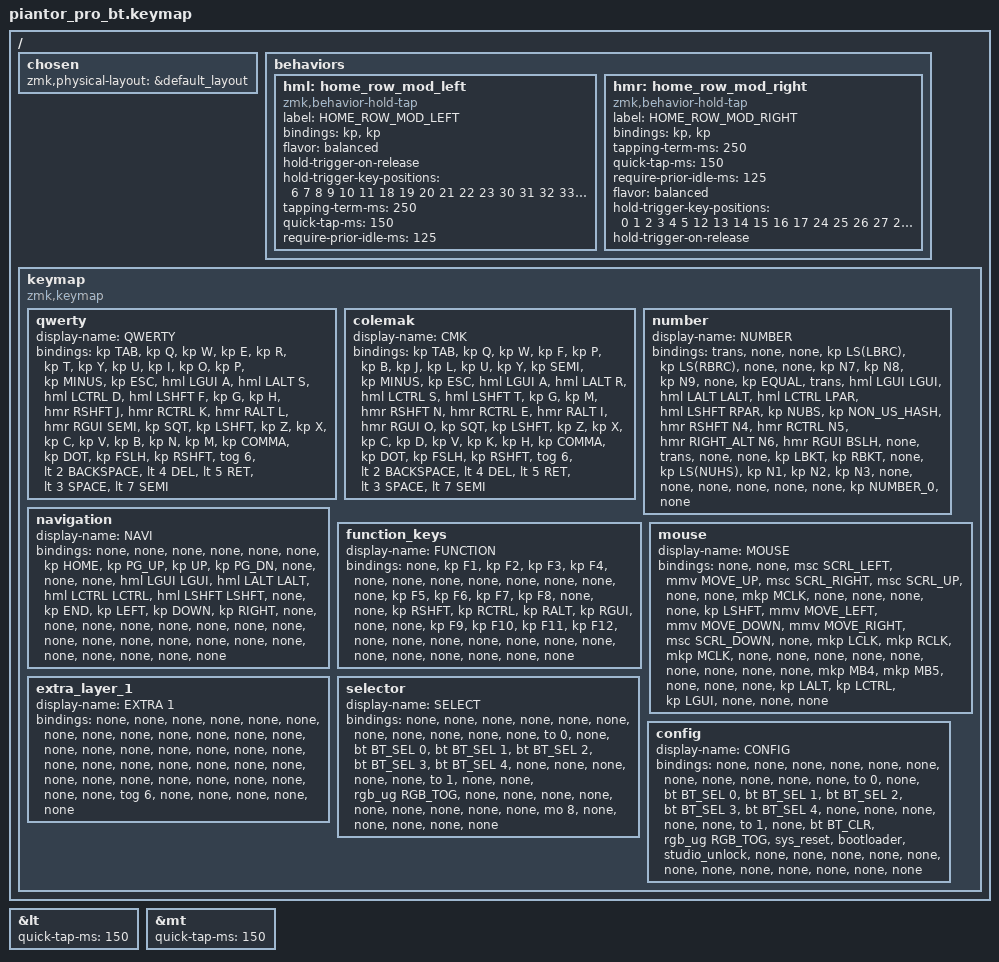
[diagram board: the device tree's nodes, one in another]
/*
 * Copyright (c) 2020 The ZMK Contributors
 *
 * SPDX-License-Identifier: MIT
 */

#include <behaviors.dtsi>
#include <dt-bindings/zmk/bt.h>
#include <dt-bindings/zmk/keys.h>
#include <dt-bindings/zmk/pointing.h>
#include <dt-bindings/zmk/rgb.h>

&lt { quick-tap-ms = <150>; };

&mt { quick-tap-ms = <150>; };

/ {
    chosen { zmk,physical-layout = &default_layout; };
};

/ {
    behaviors {
        hml: home_row_mod_left {
            compatible = "zmk,behavior-hold-tap";
            label = "HOME_ROW_MOD_LEFT";
            bindings = <&kp>, <&kp>;

            #binding-cells = <2>;
            flavor = "balanced";
            hold-trigger-on-release;
            hold-trigger-key-positions = <6 7 8 9 10 11 18 19 20 21 22 23 30 31 32 33 34 35 39 40 41 36 37 38>;
            tapping-term-ms = <250>;
            quick-tap-ms = <150>;
            require-prior-idle-ms = <125>;
        };

        hmr: home_row_mod_right {
            compatible = "zmk,behavior-hold-tap";
            label = "HOME_ROW_MOD_RIGHT";
            bindings = <&kp>, <&kp>;

            #binding-cells = <2>;
            tapping-term-ms = <250>;
            quick-tap-ms = <150>;
            require-prior-idle-ms = <125>;
            flavor = "balanced";
            hold-trigger-key-positions = <0 1 2 3 4 5 12 13 14 15 16 17 24 25 26 27 28 29 36 37 38>;
            hold-trigger-on-release;
        };
    };

    keymap {
        compatible = "zmk,keymap";

        qwerty {
            display-name = "QWERTY";
            bindings = <
&kp TAB  &kp Q  &kp W  &kp E  &kp R  &kp T  &kp Y  &kp U  &kp I  &kp O  &kp P  &kp MINUS  &kp ESC  &hml LGUI A  &hml LALT S  &hml LCTRL D  &hml LSHFT F  &kp G  &kp H  &hmr RSHFT J  &hmr RCTRL K  &hmr RALT L  &hmr RGUI SEMI  &kp SQT  &kp LSHFT  &kp Z  &kp X  &kp C  &kp V  &kp B  &kp N  &kp M  &kp COMMA  &kp DOT  &kp FSLH  &kp RSHFT  &tog 6  &lt 2 BACKSPACE  &lt 4 DEL  &lt 5 RET  &lt 3 SPACE  &lt 7 SEMI
            >;
        };

        colemak {
            display-name = "CMK";
            bindings = <
&kp TAB  &kp Q  &kp W  &kp F  &kp P  &kp B  &kp J  &kp L  &kp U  &kp Y  &kp SEMI  &kp MINUS  &kp ESC  &hml LGUI A  &hml LALT R  &hml LCTRL S  &hml LSHFT T  &kp G  &kp M  &hmr RSHFT N  &hmr RCTRL E  &hmr RALT I  &hmr RGUI O  &kp SQT  &kp LSHFT  &kp Z  &kp X  &kp C  &kp D  &kp V  &kp K  &kp H  &kp COMMA  &kp DOT  &kp FSLH  &kp RSHFT  &tog 6  &lt 2 BACKSPACE  &lt 4 DEL  &lt 5 RET  &lt 3 SPACE  &lt 7 SEMI
            >;
        };

        number {
            display-name = "NUMBER";
            bindings = <
&trans  &none  &none  &kp LS(LBRC)  &kp LS(RBRC)  &none  &none  &kp N7  &kp N8  &kp N9  &none  &kp EQUAL  &trans  &hml LGUI LGUI  &hml LALT LALT  &hml LCTRL LPAR  &hml LSHFT RPAR  &kp NUBS  &kp NON_US_HASH  &hmr RSHFT N4  &hmr RCTRL N5  &hmr RIGHT_ALT N6  &hmr RGUI BSLH  &none  &trans  &none  &none  &kp LBKT  &kp RBKT  &none  &kp LS(NUHS)  &kp N1  &kp N2  &kp N3  &none  &none  &none  &none  &none  &none  &kp NUMBER_0  &none
            >;
        };

        navigation {
            display-name = "NAVI";
            bindings = <
&none  &none  &none  &none  &none  &none  &kp HOME  &kp PG_UP  &kp UP  &kp PG_DN  &none  &none  &none  &hml LGUI LGUI  &hml LALT LALT  &hml LCTRL LCTRL  &hml LSHFT LSHFT  &none  &kp END  &kp LEFT  &kp DOWN  &kp RIGHT  &none  &none  &none  &none  &none  &none  &none  &none  &none  &none  &none  &none  &none  &none  &none  &none  &none  &none  &none  &none
            >;
        };

        function_keys {
            display-name = "FUNCTION";
            bindings = <
&none  &kp F1  &kp F2  &kp F3  &kp F4  &none  &none  &none  &none  &none  &none  &none  &none  &kp F5  &kp F6  &kp F7  &kp F8  &none  &none  &kp RSHFT  &kp RCTRL  &kp RALT  &kp RGUI  &none  &none  &kp F9  &kp F10  &kp F11  &kp F12  &none  &none  &none  &none  &none  &none  &none  &none  &none  &none  &none  &none  &none
            >;
        };

        mouse {
            display-name = "MOUSE";
            bindings = <
&none  &none  &msc SCRL_LEFT  &mmv MOVE_UP  &msc SCRL_RIGHT  &msc SCRL_UP  &none  &none  &mkp MCLK  &none  &none  &none  &none  &kp LSHFT  &mmv MOVE_LEFT  &mmv MOVE_DOWN  &mmv MOVE_RIGHT  &msc SCRL_DOWN  &none  &mkp LCLK  &mkp RCLK  &mkp MCLK  &none  &none  &none  &none  &none  &none  &none  &none  &none  &mkp MB4  &mkp MB5  &none  &none  &none  &kp LALT  &kp LCTRL  &kp LGUI  &none  &none  &none
            >;
        };

        extra_layer_1 {
            display-name = "EXTRA 1";
            bindings = <
&none  &none  &none  &none  &none  &none  &none  &none  &none  &none  &none  &none  &none  &none  &none  &none  &none  &none  &none  &none  &none  &none  &none  &none  &none  &none  &none  &none  &none  &none  &none  &none  &none  &none  &none  &none  &tog 6  &none  &none  &none  &none  &none
            >;
        };

        selector {
            display-name = "SELECT";
            bindings = <
&none  &none  &none  &none  &none  &none  &none  &none  &none  &none  &none  &to 0  &none  &bt BT_SEL 0  &bt BT_SEL 1  &bt BT_SEL 2  &bt BT_SEL 3  &bt BT_SEL 4  &none  &none  &none  &none  &none  &to 1  &none  &none  &rgb_ug RGB_TOG  &none  &none  &none  &none  &none  &none  &none  &none  &none  &mo 8  &none  &none  &none  &none  &none
            >;
        };

        config {
            display-name = "CONFIG";
            bindings = <
&none  &none  &none  &none  &none  &none  &none  &none  &none  &none  &none  &to 0  &none  &bt BT_SEL 0  &bt BT_SEL 1  &bt BT_SEL 2  &bt BT_SEL 3  &bt BT_SEL 4  &none  &none  &none  &none  &none  &to 1  &none  &bt BT_CLR  &rgb_ug RGB_TOG  &sys_reset  &bootloader  &studio_unlock  &none  &none  &none  &none  &none  &none  &none  &none  &none  &none  &none  &none
            >;
        };
    };
};
